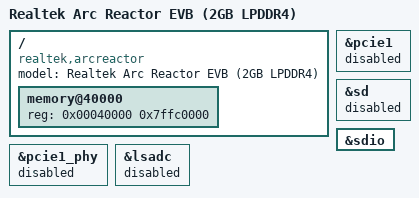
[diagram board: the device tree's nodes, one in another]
// SPDX-License-Identifier: (GPL-2.0-or-later OR BSD-2-Clause)
/*
 * Copyright (c) 2020-2022 Realtek Semiconductor Corp.
 */

/dts-v1/;

#include "rtd1315c-arcreactor.dtsi"

/ {
	compatible = "realtek,arcreactor", "realtek,rtd1315c";
	model = "Realtek Arc Reactor EVB (2GB LPDDR4)";

	memory@40000 {
		device_type = "memory";
		reg = <0x00040000 0x7ffc0000>; /* 2 GB */
	};
};

&pcie1 {
	status = "disabled";
};

&pcie1_phy {
	status = "disabled";
};

&sd {
	status = "disabled";
};

&sdio {
	status = "okay";
};

&lsadc {
	status = "disabled";
};
